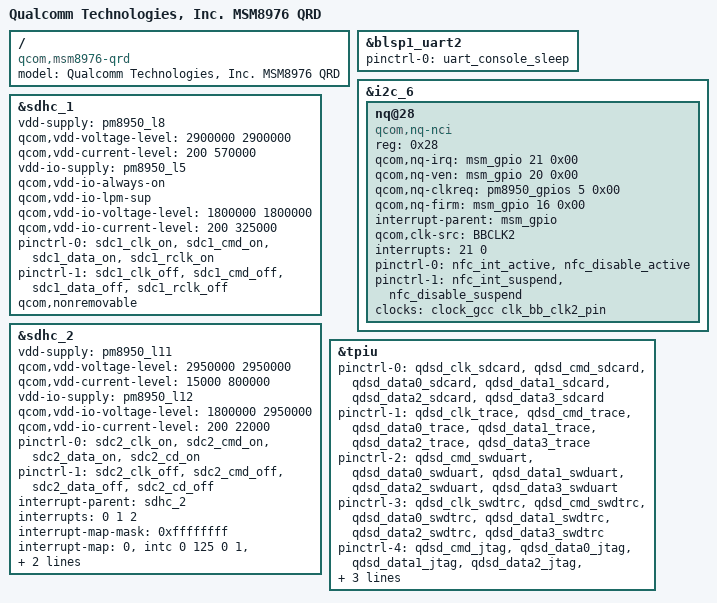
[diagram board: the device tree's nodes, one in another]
/*
 * Copyright (c) 2015, The Linux Foundation. All rights reserved.
 *
 * This program is free software; you can redistribute it and/or modify
 * it under the terms of the GNU General Public License version 2 and
 * only version 2 as published by the Free Software Foundation.
 *
 * This program is distributed in the hope that it will be useful,
 * but WITHOUT ANY WARRANTY; without even the implied warranty of
 * MERCHANTABILITY or FITNESS FOR A PARTICULAR PURPOSE.  See the
 * GNU General Public License for more details.
 */

#include "msm8976-camera-sensor-qrd.dtsi"
#include "msm8976-wsa881x.dtsi"

/ {
	model = "Qualcomm Technologies, Inc. MSM8976 QRD";
	compatible = "qcom,msm8976-qrd", "qcom,msm8976", "qcom,qrd";
};

&blsp1_uart2 {
	status = "ok";
	pinctrl-names = "default";
	pinctrl-0 = <&uart_console_sleep>;
};

&i2c_6 { /* BLSP2 QUP2 */
	nq@28 {
		compatible = "qcom,nq-nci";
		reg = <0x28>;
		qcom,nq-irq = <&msm_gpio 21 0x00>;
		qcom,nq-ven = <&msm_gpio 20 0x00>;
		qcom,nq-clkreq = <&pm8950_gpios 5 0x00>;
		qcom,nq-firm = <&msm_gpio 16 0x00>;
		interrupt-parent = <&msm_gpio>;
		qcom,clk-src = "BBCLK2";
		interrupts = <21 0>;
		interrupt-names = "nfc_irq";
		pinctrl-names = "nfc_active", "nfc_suspend";
		pinctrl-0 = <&nfc_int_active &nfc_disable_active>;
		pinctrl-1 = <&nfc_int_suspend &nfc_disable_suspend>;
		clocks = <&clock_gcc clk_bb_clk2_pin>;
		clock-names = "ref_clk";
	};
};

&sdhc_1 {
	vdd-supply = <&pm8950_l8>;
	qcom,vdd-voltage-level = <2900000 2900000>;
	qcom,vdd-current-level = <200 570000>;

	vdd-io-supply = <&pm8950_l5>;
	qcom,vdd-io-always-on;
	qcom,vdd-io-lpm-sup;
	qcom,vdd-io-voltage-level = <1800000 1800000>;
	qcom,vdd-io-current-level = <200 325000>;

	pinctrl-names = "active", "sleep";
	pinctrl-0 = <&sdc1_clk_on &sdc1_cmd_on &sdc1_data_on &sdc1_rclk_on>;
	pinctrl-1 = <&sdc1_clk_off &sdc1_cmd_off &sdc1_data_off &sdc1_rclk_off>;

	qcom,nonremovable;

	status = "ok";
};

&sdhc_2 {
	vdd-supply = <&pm8950_l11>;
	qcom,vdd-voltage-level = <2950000 2950000>;
	qcom,vdd-current-level = <15000 800000>;

	vdd-io-supply = <&pm8950_l12>;
	qcom,vdd-io-voltage-level = <1800000 2950000>;
	qcom,vdd-io-current-level = <200 22000>;

	pinctrl-names = "active", "sleep";
	pinctrl-0 = <&sdc2_clk_on &sdc2_cmd_on &sdc2_data_on &sdc2_cd_on>;
	pinctrl-1 = <&sdc2_clk_off &sdc2_cmd_off &sdc2_data_off &sdc2_cd_off>;

	#address-cells = <0>;
	interrupt-parent = <&sdhc_2>;
	interrupts = <0 1 2>;
	#interrupt-cells = <1>;
	interrupt-map-mask = <0xffffffff>;
	interrupt-map = <0 &intc 0 125 0
			1 &intc 0 221 0
			2 &msm_gpio 100 0>;
	interrupt-names = "hc_irq", "pwr_irq", "status_irq";
	cd-gpios = <&msm_gpio 100 0x1>;

	status = "ok";
};

/* CoreSight */
&tpiu {
	pinctrl-names = "sdcard", "trace", "swduart",
			"swdtrc", "jtag", "spmi";
	/* NIDnT */
	pinctrl-0 = <&qdsd_clk_sdcard &qdsd_cmd_sdcard
		     &qdsd_data0_sdcard &qdsd_data1_sdcard
		     &qdsd_data2_sdcard &qdsd_data3_sdcard>;
	pinctrl-1 = <&qdsd_clk_trace &qdsd_cmd_trace
		     &qdsd_data0_trace &qdsd_data1_trace
		     &qdsd_data2_trace &qdsd_data3_trace>;
	pinctrl-2 = <&qdsd_cmd_swduart &qdsd_data0_swduart
		     &qdsd_data1_swduart &qdsd_data2_swduart
		     &qdsd_data3_swduart>;
	pinctrl-3 = <&qdsd_clk_swdtrc &qdsd_cmd_swdtrc
		     &qdsd_data0_swdtrc &qdsd_data1_swdtrc
		     &qdsd_data2_swdtrc &qdsd_data3_swdtrc>;
	pinctrl-4 = <&qdsd_cmd_jtag &qdsd_data0_jtag
		     &qdsd_data1_jtag &qdsd_data2_jtag
		     &qdsd_data3_jtag>;
	pinctrl-5 = <&qdsd_clk_spmi &qdsd_cmd_spmi
		     &qdsd_data0_spmi &qdsd_data3_spmi>;
};
